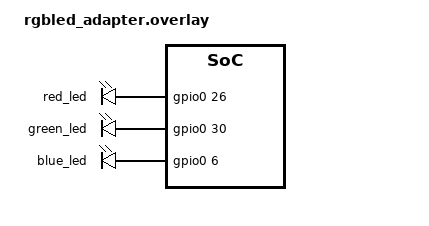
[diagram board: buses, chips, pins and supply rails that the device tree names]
#include <zephyr/dt-bindings/gpio/gpio.h>

/ {
    aliases {
        led-red = &red_led;
        led-green = &green_led;
        led-blue = &blue_led;
    };

    leds {
        compatible = "gpio-leds";

        red_led: red_led {
            gpios = <&gpio0 26 GPIO_ACTIVE_HIGH>;
        };

        green_led: green_led {
            gpios = <&gpio0 30 GPIO_ACTIVE_HIGH>;
        };

        blue_led: blue_led {
            gpios = <&gpio0 6 GPIO_ACTIVE_HIGH>;
        };
    };
};
